# STM32H5E5xx register map
File version: 1.0
Registers are 32-bit, read-write, reset 0x0 unless marked. A register's access mark holds for its fields unless they carry their own. Offsets are from the block's base; [hi:lo] are bit positions.

## COMP1
Base 0x4000400C
Same registers: COMP2 0x40004010, COMP1_S 0x5000400C, COMP2_S 0x50004010
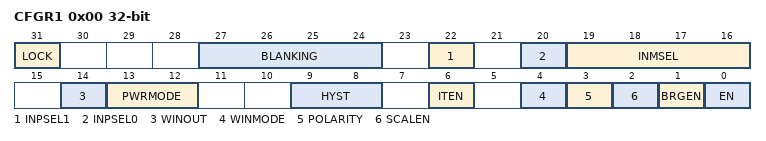
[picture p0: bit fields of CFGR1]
0x00 CFGR1 — Comparator configuration register
  [31] LOCK — COMP1 Lock Bit
  [27:24] BLANKING — COMP1 blanking source selection bits
    0=NONE (Comparator output without blanking); 1=TIM1_OC5 (Comparator output blanking source TIM1 OC5); 2=TIM2_OC3 (Comparator output blanking source TIM2 OC3); 3=TIM3_OC3; 4=TIM3_OC4 (Comparator output blanking source TIM3 OC4); 5=LPTIM1_OC2; 6=LPTIM2_OC2
  [22] INPSEL1 — COMP1 input plus 1 selection bit
  [20] INPSEL0 — COMP1 input plus 0 selection bit
  [19:16] INMSEL — COMP1 input minus selection bit
  [14] WINOUT — COMP1 window output selection bit
  [13:12] PWRMODE — COMP1 Power Mode of the comparator
    0=HIGHSPEED (COMP power mode to high speed); 1=MEDIUMSPEED (COMP power mode to medium speed); 3=ULTRALOWPOWER
  [9:8] HYST — COMP1 hysteresis selection bits
    0=NONE (No hysteresis); 1=LOW (Hysteresis level low); 2=MEDIUM (Hysteresis level medium); 3=HIGH (Hysteresis level high)
  [6] ITEN — COMP1 interrupt enable
  [4] WINMODE — COMP1 window mode selection bit
  [3] POLARITY — COMP1 polarity selection bit
    0=NONINVERTED; 1=INVERTED
  [2] SCALEN — COMP1 Voltage scaler enable bit
  [1] BRGEN — COMP1 Scaler bridge enable
  [0] EN — COMP1 enable bit

## CRS — Clock Recovery System
Base 0x40006000
Same registers: CRS_S 0x50006000
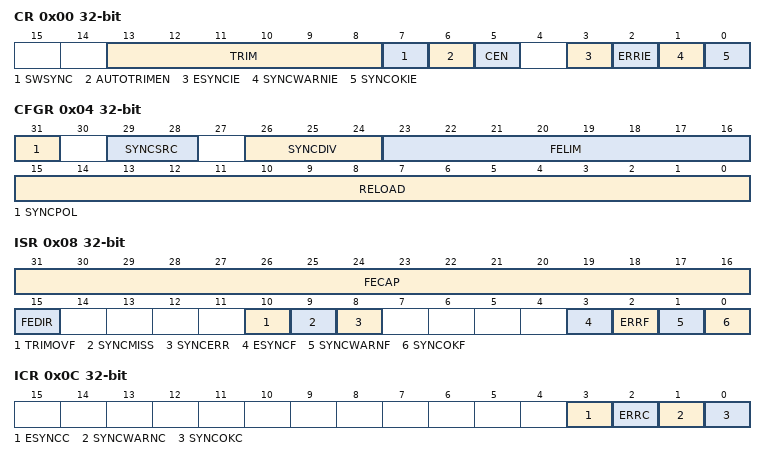
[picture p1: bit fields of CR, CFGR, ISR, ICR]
0x00 CR — CRS ccontrol register
  [13:8] TRIM — HSI48 oscillator smooth trimming
  [7] SWSYNC — Generate software SYNC event
  [6] AUTOTRIMEN — Automatic trimming enable
  [5] CEN — Frequency error counter enable
  [3] ESYNCIE — Expected SYNC interrupt enable
  [2] ERRIE — SYNC error or trimming error interrupt enable
  [1] SYNCWARNIE — SYNC warning interrupt enable
  [0] SYNCOKIE — SYNC event OK interrupt enable
0x04 CFGR — CRS configuration register
  [31] SYNCPOL — SYNC polarity selection
    0=RISING (Synchro Active on rising edge (default)); 1=FALLING (Synchro Active on falling edge)
  [29:28] SYNCSRC — SYNC signal source selection
    0=GPIO (Synchro Signal source GPIO); 1=LSE (Synchro Signal source LSE); 2=OTG_FS (Synchro Signal source OTG_FS SOF (default)); 3=OTG_HS (Synchro Signal source OTG_HS SOF)
  [26:24] SYNCDIV — SYNC divider
    0=DIV_1 (Synchro Signal not divided (default)); 1=DIV_2 (Synchro Signal divided by 2); 2=DIV_4 (Synchro Signal divided by 4); 3=DIV_8 (Synchro Signal divided by 8); 4=DIV_16 (Synchro Signal divided by 16); 5=DIV_32 (Synchro Signal divided by 32); 6=DIV_64 (Synchro Signal divided by 64); 7=DIV_128 (Synchro Signal divided by 128)
  [23:16] FELIM — Frequency error limit
  [15:0] RELOAD — Counter reload value
0x08 ISR — CRS interrupt and status register
  [31:16] FECAP — Frequency error capture
  [15] FEDIR — Frequency error direction
    0=UP (Upcounting direction, the actual frequency is above the target); 1=DOWN (Downcounting direction, the actual frequency is below the target)
  [10] TRIMOVF — Trimming overflow or underflow
  [9] SYNCMISS — SYNC missed
  [8] SYNCERR — SYNC error
  [3] ESYNCF — Expected SYNC flag
  [2] ERRF — Error flag
  [1] SYNCWARNF — SYNC warning flag
  [0] SYNCOKF — SYNC event OK flag
0x0C ICR — CRS interrupt flag clear register
  [3] ESYNCC — Expected SYNC clear flag
  [2] ERRC — Error clear flag
  [1] SYNCWARNC — SYNC warning clear flag
  [0] SYNCOKC — SYNC event OK clear flag

## CEC — Consumer Electronics Control
Base 0x40007000
Same registers: CEC_S 0x50007000
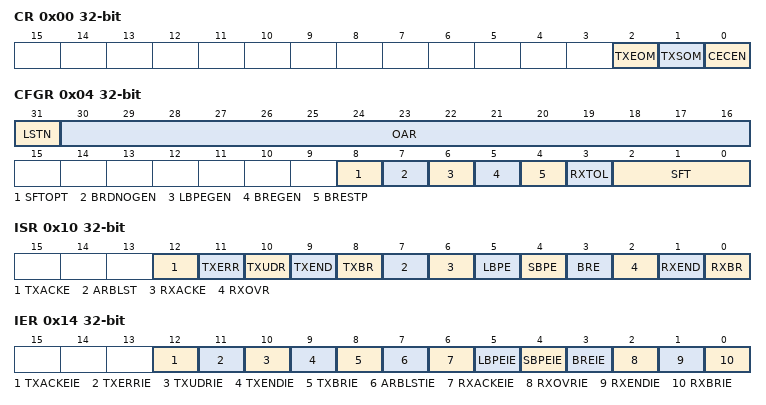
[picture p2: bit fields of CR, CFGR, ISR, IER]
0x00 CR — CEC control register
  [2] TXEOM — CEC Tx End Of Message
  [1] TXSOM — CEC Tx Start Of Message
  [0] CECEN — CEC Enable
0x04 CFGR — CEC configuration register
  [31] LSTN — CEC Listen mode
  [30:16] OAR — CEC Own Address
  [8] SFTOPT — CEC Signal Free Time optional
  [7] BRDNOGEN — CEC Broadcast No error generation
  [6] LBPEGEN — CEC Long Bit Period Error generation
  [5] BREGEN — CEC Bit Rising Error generation
  [4] BRESTP — CEC Rx Stop
  [3] RXTOL — CEC Tolerance
  [2:0] SFT — CEC Signal Free Time
0x08 TXDR — CEC Tx data register
  [7:0] TXD — CEC Tx Data
0x0C RXDR — CEC Rx Data Register
  [7:0] RXD — CEC Rx Data
0x10 ISR — CEC Interrupt and Status Register
  [12] TXACKE — CEC Tx Missing Acknowledge
  [11] TXERR — CEC Tx-Error
  [10] TXUDR — CEC Tx-Buffer Underrun
  [9] TXEND — CEC End of Transmission
  [8] TXBR — CEC Tx Byte Request
  [7] ARBLST — CEC Arbitration Lost
  [6] RXACKE — CEC Rx Missing Acknowledge
  [5] LBPE — CEC Rx Long Bit period Error
  [4] SBPE — CEC Rx Short Bit period Error
  [3] BRE — CEC Rx Bit Rising Error
  [2] RXOVR — CEC Rx-Overrun
  [1] RXEND — CEC End Of Reception
  [0] RXBR — CEC Rx-Byte Received
0x14 IER — CEC interrupt enable register
  [12] TXACKEIE — CEC Tx Missing Acknowledge IT Enable
  [11] TXERRIE — CEC Tx-Error IT Enable
  [10] TXUDRIE — CEC Tx-Buffer Underrun IT Enable
  [9] TXENDIE — CEC End of Transmission IT Enable
  [8] TXBRIE — CEC Tx Byte Request IT Enable
  [7] ARBLSTIE — CEC Arbitration Lost IT Enable
  [6] RXACKEIE — CEC Rx Missing Acknowledge IT Enable
  [5] LBPEIE — CEC Rx Long Bit period Error IT Enable
  [4] SBPEIE — CEC Rx Short Bit period Error IT Enable
  [3] BREIE — CEC Rx Bit Rising Error IT Enable
  [2] RXOVRIE — CEC Rx-Overrun IT Enable
  [1] RXENDIE — CEC End Of Reception IT Enable
  [0] RXBRIE — CEC Rx-Byte Received IT Enable
